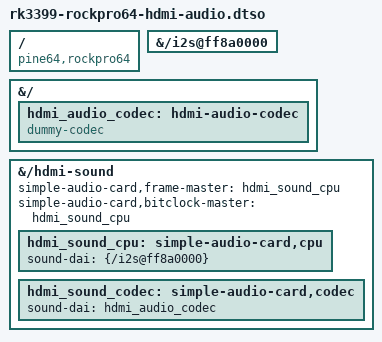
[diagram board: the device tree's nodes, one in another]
/*
 * RockPro64 HDMI audio overlay.
 *
 * Wires the on-chip-only I2S2 audio output to a dummy codec so
 * FreeBSD's audio_soc binder creates a /dev/dsp0 sound device.  The
 * actual HDMI audio packetizer programming (CTS/N, AudioInfoFrame)
 * lives in rk_drm_hw.c; this overlay only exists so audio_soc has
 * both ends of the DAI link to bind.
 *
 * NOTE: The base rk3399-rockpro64.dtsi already declares a stub
 * hdmi-sound node (compatible = "simple-audio-card") without the
 * required simple-audio-card,cpu / simple-audio-card,codec children
 * and without an hdmi-audio-codec sibling node.  Re-declaring
 * hdmi-sound at root in this overlay would conflict; instead we
 * patch the existing node via &{/hdmi-sound} and add the missing
 * codec sibling at root.
 *
 * Build: included automatically by sys/dts/arm64/overlays/Makefile.
 * Install: cp .dtbo to /boot/dtb/overlays/, then in /boot/loader.conf:
 *     fdt_overlays="rk3399-rockpro64-hdmi-audio"
 */

/dts-v1/;
/plugin/;

/ {
	compatible = "pine64,rockpro64";
};

/* Enable the I2S2 controller (it ships disabled in rk3399-base.dtsi). */
&{/i2s@ff8a0000} {
	status = "okay";
};

/*
 * Add the dummy codec at root (sibling of hdmi-sound).  audio_soc
 * resolves &hdmi_audio_codec via this label so the codec attach
 * succeeds and pcm_register() actually fires.
 */
&{/} {
	hdmi_audio_codec: hdmi-audio-codec {
		compatible = "dummy-codec";
		#sound-dai-cells = <0>;
		status = "okay";
	};
};

/*
 * Patch the existing /hdmi-sound (from base DTSI) — add the two
 * required simple-audio-card child nodes that name the CPU + codec
 * DAI references.  Without these audio_soc can't construct the link
 * and the pcm device never appears.
 */
&{/hdmi-sound} {
	simple-audio-card,frame-master = <&hdmi_sound_cpu>;
	simple-audio-card,bitclock-master = <&hdmi_sound_cpu>;
	status = "okay";

	hdmi_sound_cpu: simple-audio-card,cpu {
		sound-dai = <&{/i2s@ff8a0000}>;
	};

	hdmi_sound_codec: simple-audio-card,codec {
		sound-dai = <&hdmi_audio_codec>;
	};
};

/* vim: set ft=dts: */
